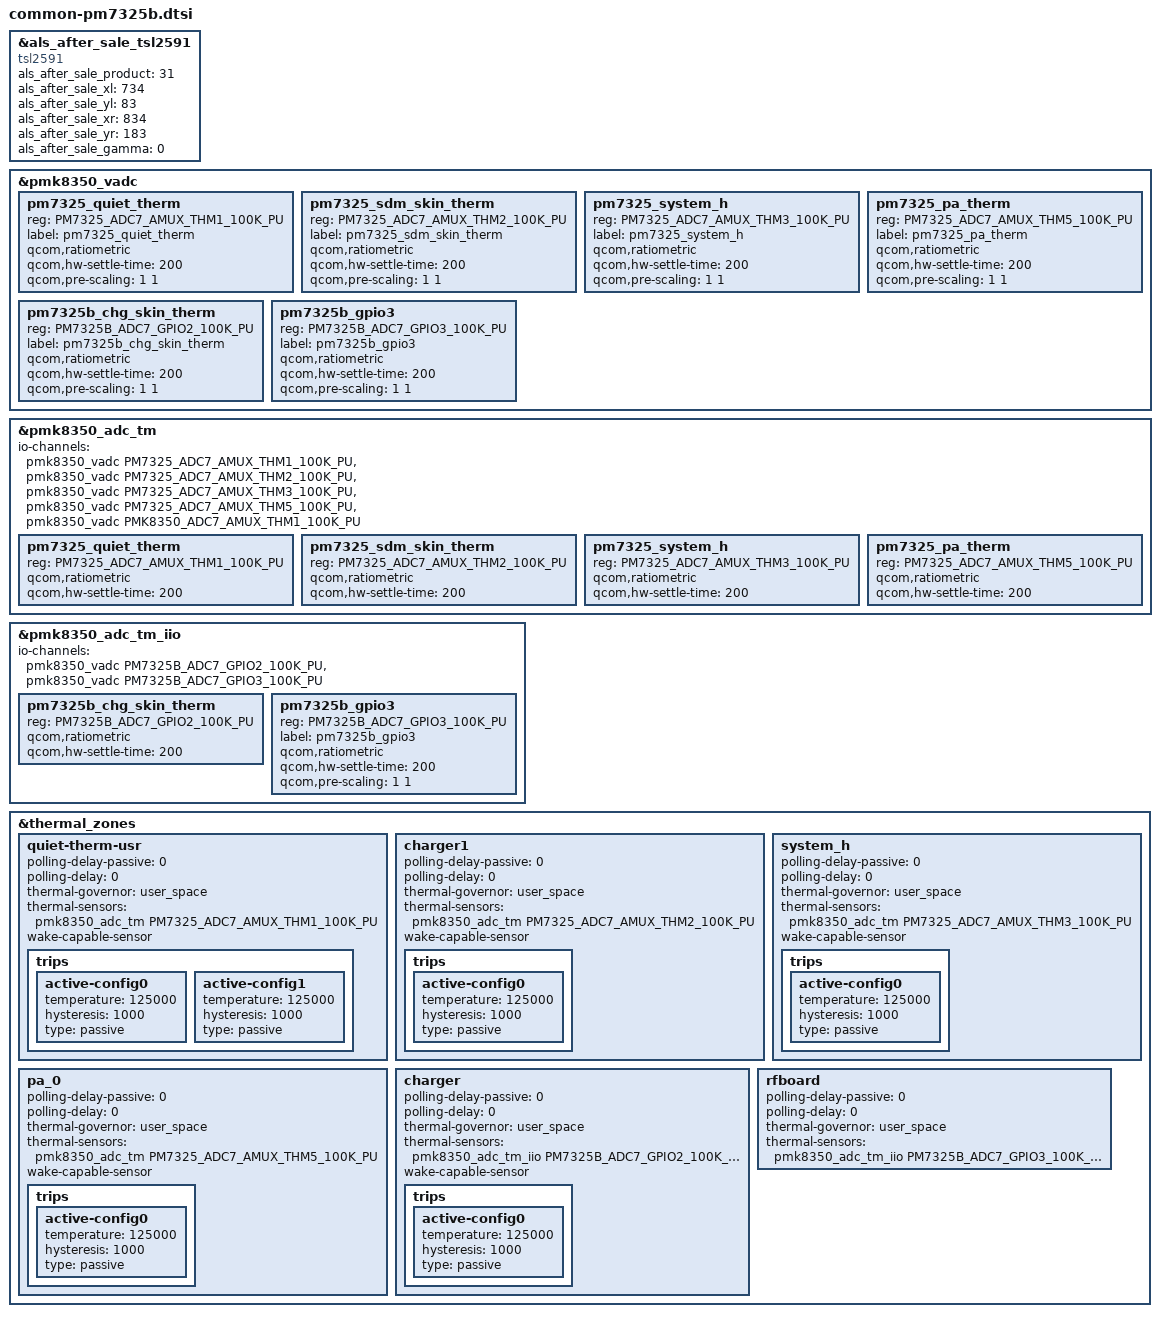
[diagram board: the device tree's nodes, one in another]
#include "../../../yupik-idp.dtsi"
#include "../../common/huawei_dev_detect/huawei_dev_detect.dtsi"
#include <dt-bindings/pinctrl/qcom,pmic-gpio.h>
#include <dt-bindings/iio/qcom,spmi-adc7-pm7325.h>
#include <dt-bindings/iio/qcom,spmi-adc7-pm7325b.h>
#include "huawei_audio.dtsi"
#include "huawei-sensor.dtsi"
#include "huawei_tp.dtsi"
#include "huawei-lcd.dtsi"
#include "huawei_usb.dtsi"
#include "huawei_charger.dtsi"
#include "huawei_bt.dtsi"
#include "huawei_fac.dtsi"
#include "huawei_bsp.dtsi"
#include "huawei_fp.dtsi"

&als_after_sale_tsl2591 {
    compatible = "tsl2591";
    als_after_sale_product = <31>;
    als_after_sale_xl = <734>;
    als_after_sale_yl = <83>;
    als_after_sale_xr = <834>;
    als_after_sale_yr = <183>;
    als_after_sale_gamma = <0>;
};

&pmk8350_vadc {

	pm7325_quiet_therm {
		reg = <PM7325_ADC7_AMUX_THM1_100K_PU>;
		label = "pm7325_quiet_therm";
		qcom,ratiometric;
		qcom,hw-settle-time = <200>;
		qcom,pre-scaling = <1 1>;
	};

	pm7325_sdm_skin_therm {
		reg = <PM7325_ADC7_AMUX_THM2_100K_PU>;
		label = "pm7325_sdm_skin_therm";
		qcom,ratiometric;
		qcom,hw-settle-time = <200>;
		qcom,pre-scaling = <1 1>;
	};

	pm7325_system_h {
		reg = <PM7325_ADC7_AMUX_THM3_100K_PU>;
		label = "pm7325_system_h";
		qcom,ratiometric;
		qcom,hw-settle-time = <200>;
		qcom,pre-scaling = <1 1>;
	};

	pm7325_pa_therm {
		reg = <PM7325_ADC7_AMUX_THM5_100K_PU>;
		label = "pm7325_pa_therm";
		qcom,ratiometric;
		qcom,hw-settle-time = <200>;
		qcom,pre-scaling = <1 1>;
	};

	pm7325b_chg_skin_therm {
		reg = <PM7325B_ADC7_GPIO2_100K_PU>;
		label = "pm7325b_chg_skin_therm";
		qcom,ratiometric;
		qcom,hw-settle-time = <200>;
		qcom,pre-scaling = <1 1>;
	};

	pm7325b_gpio3 {
		reg = <PM7325B_ADC7_GPIO3_100K_PU>;
		label = "pm7325b_gpio3";
		qcom,ratiometric;
		qcom,hw-settle-time = <200>;
		qcom,pre-scaling = <1 1>;
    };
};

&pmk8350_adc_tm {
	io-channels = <&pmk8350_vadc PM7325_ADC7_AMUX_THM1_100K_PU>,
			<&pmk8350_vadc PM7325_ADC7_AMUX_THM2_100K_PU>,
			<&pmk8350_vadc PM7325_ADC7_AMUX_THM3_100K_PU>,
			<&pmk8350_vadc PM7325_ADC7_AMUX_THM5_100K_PU>,
			<&pmk8350_vadc PMK8350_ADC7_AMUX_THM1_100K_PU>;

	pm7325_quiet_therm {
		reg = <PM7325_ADC7_AMUX_THM1_100K_PU>;
		qcom,ratiometric;
		qcom,hw-settle-time = <200>;
	};

	pm7325_sdm_skin_therm {
		reg = <PM7325_ADC7_AMUX_THM2_100K_PU>;
		qcom,ratiometric;
		qcom,hw-settle-time = <200>;
	};

	pm7325_system_h {
		reg = <PM7325_ADC7_AMUX_THM3_100K_PU>;
		qcom,ratiometric;
		qcom,hw-settle-time = <200>;
	};

	pm7325_pa_therm {
		reg = <PM7325_ADC7_AMUX_THM5_100K_PU>;
		qcom,ratiometric;
		qcom,hw-settle-time = <200>;
	};
};

&pmk8350_adc_tm_iio {
	io-channels =<&pmk8350_vadc PM7325B_ADC7_GPIO2_100K_PU>,
                     <&pmk8350_vadc PM7325B_ADC7_GPIO3_100K_PU>;

	pm7325b_chg_skin_therm {
		reg = <PM7325B_ADC7_GPIO2_100K_PU>;
		qcom,ratiometric;
		qcom,hw-settle-time = <200>;
	};

	pm7325b_gpio3 {
		reg = <PM7325B_ADC7_GPIO3_100K_PU>;
		label = "pm7325b_gpio3";
		qcom,ratiometric;
		qcom,hw-settle-time = <200>;
		qcom,pre-scaling = <1 1>;
    };
};

&thermal_zones {
	quiet-therm-usr {
		polling-delay-passive = <0>;
		polling-delay = <0>;
		thermal-governor = "user_space";
		thermal-sensors = <&pmk8350_adc_tm PM7325_ADC7_AMUX_THM1_100K_PU>;
		wake-capable-sensor;
		trips {
			active-config0 {
				temperature = <125000>;
				hysteresis = <1000>;
				type = "passive";
			};

			active-config1 {
				temperature = <125000>;
				hysteresis = <1000>;
				type = "passive";
			};
		};
	};

	charger1 {
		polling-delay-passive = <0>;
		polling-delay = <0>;
		thermal-governor = "user_space";
		thermal-sensors = <&pmk8350_adc_tm PM7325_ADC7_AMUX_THM2_100K_PU>;
		wake-capable-sensor;
		trips {
			active-config0 {
				temperature = <125000>;
				hysteresis = <1000>;
				type = "passive";
			};
		};
	};

	system_h {
		polling-delay-passive = <0>;
		polling-delay = <0>;
		thermal-governor = "user_space";
		thermal-sensors = <&pmk8350_adc_tm PM7325_ADC7_AMUX_THM3_100K_PU>;
		wake-capable-sensor;
		trips {
			active-config0 {
				temperature = <125000>;
				hysteresis = <1000>;
				type = "passive";
			};
		};
	};

	pa_0 {
		polling-delay-passive = <0>;
		polling-delay = <0>;
		thermal-governor = "user_space";
		thermal-sensors = <&pmk8350_adc_tm PM7325_ADC7_AMUX_THM5_100K_PU>;
		wake-capable-sensor;
		trips {
			active-config0 {
				temperature = <125000>;
				hysteresis = <1000>;
				type = "passive";
			};
		};
	};

	charger {
		polling-delay-passive = <0>;
		polling-delay = <0>;
		thermal-governor = "user_space";
		thermal-sensors = <&pmk8350_adc_tm_iio PM7325B_ADC7_GPIO2_100K_PU>;
		wake-capable-sensor;
		trips {
			active-config0 {
				temperature = <125000>;
				hysteresis = <1000>;
				type = "passive";
			};
		};
	};
	rfboard {
		polling-delay-passive = <0>;
		polling-delay = <0>;
		thermal-governor = "user_space";
		thermal-sensors = <&pmk8350_adc_tm_iio PM7325B_ADC7_GPIO3_100K_PU>;
	};
};
